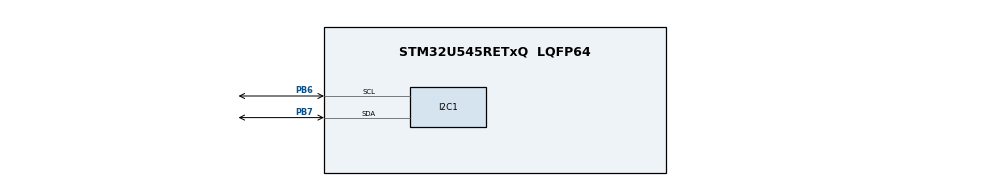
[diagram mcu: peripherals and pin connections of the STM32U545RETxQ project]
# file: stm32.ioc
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CORTEX_M33_NS.userName=CORTEX_M33
I2C1.Timing=0x00000E14
Mcu.Family=STM32U5
Mcu.Name=STM32U545RETxQ
Mcu.Package=LQFP64
NUCLEO-U545RE-Q.BUTTON=1
NUCLEO-U545RE-Q.LD2=true
NUCLEO-U545RE-Q.VCP=true
NVIC.EXTI13_IRQn=true\:0\:0\:false\:false\:true\:false\:true\:true
NVIC.PriorityGroup=NVIC_PRIORITYGROUP_4
NVIC.TIM6_IRQn=true\:15\:0\:false\:false\:true\:false\:true\:true
NVIC.TimeBase=TIM6_IRQn
NVIC.TimeBaseIP=TIM6
PB6.Mode=I2C
PB6.Signal=I2C1_SCL
PB7.Mode=I2C
PB7.Signal=I2C1_SDA
PWR.PowerMode=PWR_SMPS_SUPPLY
ProjectManager.HeapSize=0x200
ProjectManager.StackSize=0x400
ProjectManager.TargetToolchain=CMake
RCC.ADCFreq_Value=16000000
RCC.DACCLockSelectionVirtual=RCC_DAC1CLKSOURCE_LSI
RCC.DACCLockSelectionVirtualString=RCC_DAC1CLKSOURCE_LSI
RCC.EPOD_VALUE=4000000
RCC.HSE_VALUE=16000000
RCC.HSI48_VALUE=48000000
RCC.HSI_VALUE=16000000
RCC.LSE_VALUE=32768
RCC.LSIDIV_VALUE=32000
RCC.MSI_VALUE=4000000
RCC.USBFreq_Value=48000000
RCC.VCOOutputFreq_Value=516000000
VP_ICACHE_VS_ICACHE.Mode=DirectMappedCache
VP_LPBAMQUEUE_VS_QUEUE.Mode=QUEUEMODE
VP_MEMORYMAP_VS_MEMORYMAP.Mode=CurAppReg
VP_NUCLEO-U545RE-Q_VS_BSP_COMMON.Mode=COMMON
VP_PWR_VS_LPOM.Mode=PowerOptimisation
VP_PWR_VS_SECSignals.Mode=Security/Privilege
VP_SYS_VS_tim6.Mode=TIM6
board=NUCLEO-U545RE-Q

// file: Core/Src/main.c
/* USER CODE BEGIN Header */
/**
  ******************************************************************************
  * @file           : main.c
  * @brief          : Main program body
  ******************************************************************************
  * @attention
  *
  * Copyright (c) 2026 STMicroelectronics.
  * All rights reserved.
  *
  * This software is licensed under terms that can be found in the LICENSE file
  * in the root directory of this software component.
  * If no LICENSE file comes with this software, it is provided AS-IS.
  *
  ******************************************************************************
  */
/* USER CODE END Header */
#include "main.h"

/* USER CODE BEGIN Includes */
#include "application_main.h"
/* USER CODE END Includes */

COM_InitTypeDef BspCOMInit;

I2C_HandleTypeDef hi2c1;

void SystemClock_Config(void);
static void SystemPower_Config(void);
static void MX_GPIO_Init(void);
static void MX_ICACHE_Init(void);
static void MX_I2C1_Init(void);

int main(void)
{

  /* MCU Configuration--------------------------------------------------------*/

  /* Reset of all peripherals, Initializes the Flash interface and the Systick. */
  HAL_Init();

  /* Configure the System Power */
  SystemPower_Config();

  /* Configure the system clock */
  SystemClock_Config();

  /* Initialize all configured peripherals */
  MX_GPIO_Init();
  MX_ICACHE_Init();
  MX_I2C1_Init();

  /* Initialize led */
  BSP_LED_Init(LED_GREEN);

  /* Initialize USER push-button, will be used to trigger an interrupt each time it's pressed.*/
  BSP_PB_Init(BUTTON_USER, BUTTON_MODE_EXTI);

  /* Initialize COM1 port (115200, 8 bits (7-bit data + 1 stop bit), no parity */
  BspCOMInit.BaudRate   = 115200;
  BspCOMInit.WordLength = COM_WORDLENGTH_8B;
  BspCOMInit.StopBits   = COM_STOPBITS_1;
  BspCOMInit.Parity     = COM_PARITY_NONE;
  BspCOMInit.HwFlowCtl  = COM_HWCONTROL_NONE;
  if (BSP_COM_Init(COM1, &BspCOMInit) != BSP_ERROR_NONE)
  {
    Error_Handler();
  }

  /* Infinite loop */
  /* USER CODE BEGIN WHILE */

  BSP_LED_On(LED_GREEN);

  // Enter FreeRTOS Application
  appEntryPoint();

  // Should never reach here
  while (1)
  {

    /* USER CODE END WHILE */

  }
}

void SystemClock_Config(void)
{
  RCC_OscInitTypeDef RCC_OscInitStruct = {0};
  RCC_ClkInitTypeDef RCC_ClkInitStruct = {0};

  /** Configure the main internal regulator output voltage
  */
  if (HAL_PWREx_ControlVoltageScaling(PWR_REGULATOR_VOLTAGE_SCALE4) != HAL_OK)
  {
    Error_Handler();
  }

  /** Initializes the CPU, AHB and APB buses clocks
  */
  RCC_OscInitStruct.OscillatorType = RCC_OSCILLATORTYPE_MSI;
  RCC_OscInitStruct.MSIState = RCC_MSI_ON;
  RCC_OscInitStruct.MSICalibrationValue = RCC_MSICALIBRATION_DEFAULT;
  RCC_OscInitStruct.MSIClockRange = RCC_MSIRANGE_4;
  RCC_OscInitStruct.PLL.PLLState = RCC_PLL_NONE;
  if (HAL_RCC_OscConfig(&RCC_OscInitStruct) != HAL_OK)
  {
    Error_Handler();
  }

  /** Initializes the CPU, AHB and APB buses clocks
  */
  RCC_ClkInitStruct.ClockType = RCC_CLOCKTYPE_HCLK|RCC_CLOCKTYPE_SYSCLK
                              |RCC_CLOCKTYPE_PCLK1|RCC_CLOCKTYPE_PCLK2
                              |RCC_CLOCKTYPE_PCLK3;
  RCC_ClkInitStruct.SYSCLKSource = RCC_SYSCLKSOURCE_MSI;
  RCC_ClkInitStruct.AHBCLKDivider = RCC_SYSCLK_DIV1;
  RCC_ClkInitStruct.APB1CLKDivider = RCC_HCLK_DIV1;
  RCC_ClkInitStruct.APB2CLKDivider = RCC_HCLK_DIV1;
  RCC_ClkInitStruct.APB3CLKDivider = RCC_HCLK_DIV1;

  if (HAL_RCC_ClockConfig(&RCC_ClkInitStruct, FLASH_LATENCY_0) != HAL_OK)
  {
    Error_Handler();
  }
}

/**
  * @brief Power Configuration
  * @retval None
  */
static void SystemPower_Config(void)
{

  /*
   * Switch to SMPS regulator instead of LDO
   */
  if (HAL_PWREx_ConfigSupply(PWR_SMPS_SUPPLY) != HAL_OK)
  {
    Error_Handler();
  }
}

static void MX_I2C1_Init(void)
{

  hi2c1.Instance = I2C1;
  hi2c1.Init.Timing = 0x00000E14;
  hi2c1.Init.OwnAddress1 = 0;
  hi2c1.Init.AddressingMode = I2C_ADDRESSINGMODE_7BIT;
  hi2c1.Init.DualAddressMode = I2C_DUALADDRESS_DISABLE;
  hi2c1.Init.OwnAddress2 = 0;
  hi2c1.Init.OwnAddress2Masks = I2C_OA2_NOMASK;
  hi2c1.Init.GeneralCallMode = I2C_GENERALCALL_DISABLE;
  hi2c1.Init.NoStretchMode = I2C_NOSTRETCH_DISABLE;
  if (HAL_I2C_Init(&hi2c1) != HAL_OK)
  {
    Error_Handler();
  }

  /** Configure Analogue filter
  */
  if (HAL_I2CEx_ConfigAnalogFilter(&hi2c1, I2C_ANALOGFILTER_ENABLE) != HAL_OK)
  {
    Error_Handler();
  }

  /** Configure Digital filter
  */
  if (HAL_I2CEx_ConfigDigitalFilter(&hi2c1, 0) != HAL_OK)
  {
    Error_Handler();
  }

}

static void MX_ICACHE_Init(void)
{

  /** Enable instruction cache in 1-way (direct mapped cache)
  */
  if (HAL_ICACHE_ConfigAssociativityMode(ICACHE_1WAY) != HAL_OK)
  {
    Error_Handler();
  }
  if (HAL_ICACHE_Enable() != HAL_OK)
  {
    Error_Handler();
  }

}

static void MX_GPIO_Init(void)
{

  /* GPIO Ports Clock Enable */
  __HAL_RCC_GPIOB_CLK_ENABLE();

}

void HAL_TIM_PeriodElapsedCallback(TIM_HandleTypeDef *htim)
{
  if (htim->Instance == TIM6)
  {
    HAL_IncTick();
  }
}

void Error_Handler(void)
{
  __disable_irq();
  while (1)
  {
  }
}
